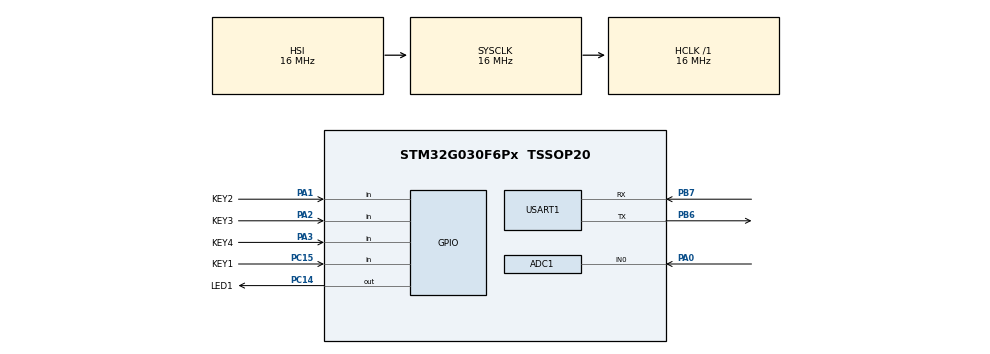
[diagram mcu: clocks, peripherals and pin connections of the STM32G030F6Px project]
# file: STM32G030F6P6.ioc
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ADC1.Channel-4\#ChannelRegularConversion=ADC_CHANNEL_0
ADC1.ContinuousConvMode=ENABLE
ADC1.DMAContinuousRequests=ENABLE
ADC1.DataAlign=ADC_DATAALIGN_RIGHT
ADC1.EOCSelection=ADC_EOC_SEQ_CONV
ADC1.NbrOfConversion=1
ADC1.NbrOfConversionFlag=1
ADC1.Overrun=ADC_OVR_DATA_PRESERVED
ADC1.Rank-4\#ChannelRegularConversion=1
ADC1.SamplingTime-4\#ChannelRegularConversion=ADC_SAMPLINGTIME_COMMON_1
ADC1.SamplingTimeCommon1=ADC_SAMPLETIME_12CYCLES_5
ADC1.SamplingTimeCommon2=ADC_SAMPLETIME_12CYCLES_5
ADC1.SelectedChannel=ADC_CHANNEL_0
ADC1.TriggerFrequencyMode=ADC_TRIGGER_FREQ_HIGH
ADC1.master=1
Dma.ADC1.0.Direction=DMA_PERIPH_TO_MEMORY
Dma.ADC1.0.EventEnable=DISABLE
Dma.ADC1.0.Instance=DMA1_Channel1
Dma.ADC1.0.MemDataAlignment=DMA_MDATAALIGN_HALFWORD
Dma.ADC1.0.MemInc=DMA_MINC_ENABLE
Dma.ADC1.0.Mode=DMA_CIRCULAR
Dma.ADC1.0.PeriphDataAlignment=DMA_PDATAALIGN_HALFWORD
Dma.ADC1.0.PeriphInc=DMA_PINC_DISABLE
Dma.ADC1.0.Polarity=HAL_DMAMUX_REQ_GEN_RISING
Dma.ADC1.0.Priority=DMA_PRIORITY_LOW
Dma.ADC1.0.RequestNumber=1
Dma.ADC1.0.SignalID=NONE
Dma.ADC1.0.SyncEnable=DISABLE
Dma.ADC1.0.SyncPolarity=HAL_DMAMUX_SYNC_NO_EVENT
Dma.ADC1.0.SyncRequestNumber=1
Dma.ADC1.0.SyncSignalID=NONE
Dma.Request0=ADC1
Mcu.Family=STM32G0
Mcu.Name=STM32G030F6Px
Mcu.Package=TSSOP20
NVIC.ADC1_IRQn=true\:0\:0\:false\:false\:true\:true\:true
NVIC.DMA1_Channel1_IRQn=true\:0\:0\:false\:false\:true\:false\:true
NVIC.USART1_IRQn=true\:0\:0\:false\:false\:true\:true\:true
PA0.GPIO_Mode=GPIO_MODE_ANALOG
PA0.GPIO_PuPd=GPIO_NOPULL
PA0.Mode=IN0
PA0.Signal=ADC1_IN0
PA1.GPIO_Label=KEY2
PA1.Signal=GPIO_Input
PA13.Mode=Serial_Wire
PA13.Signal=SYS_SWDIO
PA14-BOOT0.Mode=Serial_Wire
PA14-BOOT0.Signal=SYS_SWCLK
PA2.GPIO_Label=KEY3
PA2.Signal=GPIO_Input
PA3.GPIO_Label=KEY4
PA3.Signal=GPIO_Input
PB6.Mode=Asynchronous
PB6.Signal=USART1_TX
PB7.Mode=Asynchronous
PB7.Signal=USART1_RX
PC14-OSC32_IN\ (PC14).GPIO_Label=LED1
PC14-OSC32_IN\ (PC14).GPIO_ModeDefaultOutputPP=GPIO_MODE_OUTPUT_PP
PC14-OSC32_IN\ (PC14).PinState=GPIO_PIN_SET
PC14-OSC32_IN\ (PC14).Signal=GPIO_Output
PC15-OSC32_OUT\ (PC15).GPIO_Label=KEY1
PC15-OSC32_OUT\ (PC15).Signal=GPIO_Input
ProjectManager.HeapSize=0x200
ProjectManager.StackSize=0x400
ProjectManager.TargetToolchain=MDK-ARM V5
RCC.AHBFreq_Value=16000000
RCC.CortexFreq_Value=16000000
RCC.EXTERNAL_CLOCK_VALUE=12288000
RCC.HCLKFreq_Value=16000000
RCC.HSE_VALUE=8000000
RCC.HSI_VALUE=16000000
RCC.LSE_VALUE=32768
RCC.SYSCLKFreq_VALUE=16000000
RCC.VCOOutputFreq_Value=128000000
USART1.VirtualMode-Asynchronous=VM_ASYNC
board=custom

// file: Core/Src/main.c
/* USER CODE BEGIN Header */
/**
  ******************************************************************************
  * @file           : main.c
  * @brief          : Main program body
  ******************************************************************************
  * @attention
  *
  * <h2><center>&copy; Copyright (c) 2024 STMicroelectronics.
  * All rights reserved.</center></h2>
  *
  * This software component is licensed by ST under BSD 3-Clause license,
  * the "License"; You may not use this file except in compliance with the
  * License. You may obtain a copy of the License at:
  *                        opensource.org/licenses/BSD-3-Clause
  *
  ******************************************************************************
  */
/* USER CODE END Header */
#include "main.h"
#include "adc.h"
#include "dma.h"
#include "usart.h"
#include "gpio.h"

void SystemClock_Config(void);

int main(void)
{

  /* MCU Configuration--------------------------------------------------------*/

  /* Reset of all peripherals, Initializes the Flash interface and the Systick. */
  HAL_Init();

  /* Configure the system clock */
  SystemClock_Config();

  /* Initialize all configured peripherals */
  MX_GPIO_Init();
  MX_DMA_Init();
  MX_ADC1_Init();
  MX_USART1_UART_Init();
  /* USER CODE BEGIN 2 */

  uint16_t temp_ADC_Value;

	uint8_t tx[2];
//	temp_ADC_Value = 0x03dc;
	HAL_ADCEx_Calibration_Start(&hadc1);
	HAL_ADC_Start_DMA(&hadc1,(uint32_t*)&temp_ADC_Value, 100);
	HAL_Delay(1);

  /* USER CODE END 2 */

  /* Infinite loop */
  /* USER CODE BEGIN WHILE */
  while (1)
  {
		tx[0] =	(uint8_t)((temp_ADC_Value >> 8) & 0xFF);  //低字节
		tx[1] = (uint8_t)(temp_ADC_Value & 0xFF); //高字节
		HAL_UART_Transmit(&huart1,tx,sizeof(tx),HAL_MAX_DELAY);
		HAL_Delay(1);
    /* USER CODE END WHILE */

  }
}

void SystemClock_Config(void)
{
  RCC_OscInitTypeDef RCC_OscInitStruct = {0};
  RCC_ClkInitTypeDef RCC_ClkInitStruct = {0};
  RCC_PeriphCLKInitTypeDef PeriphClkInit = {0};

  /** Configure the main internal regulator output voltage
  */
  HAL_PWREx_ControlVoltageScaling(PWR_REGULATOR_VOLTAGE_SCALE1);
  /** Initializes the RCC Oscillators according to the specified parameters
  * in the RCC_OscInitTypeDef structure.
  */
  RCC_OscInitStruct.OscillatorType = RCC_OSCILLATORTYPE_HSI;
  RCC_OscInitStruct.HSIState = RCC_HSI_ON;
  RCC_OscInitStruct.HSIDiv = RCC_HSI_DIV1;
  RCC_OscInitStruct.HSICalibrationValue = RCC_HSICALIBRATION_DEFAULT;
  RCC_OscInitStruct.PLL.PLLState = RCC_PLL_NONE;
  if (HAL_RCC_OscConfig(&RCC_OscInitStruct) != HAL_OK)
  {
    Error_Handler();
  }
  /** Initializes the CPU, AHB and APB buses clocks
  */
  RCC_ClkInitStruct.ClockType = RCC_CLOCKTYPE_HCLK|RCC_CLOCKTYPE_SYSCLK
                              |RCC_CLOCKTYPE_PCLK1;
  RCC_ClkInitStruct.SYSCLKSource = RCC_SYSCLKSOURCE_HSI;
  RCC_ClkInitStruct.AHBCLKDivider = RCC_SYSCLK_DIV1;
  RCC_ClkInitStruct.APB1CLKDivider = RCC_HCLK_DIV1;

  if (HAL_RCC_ClockConfig(&RCC_ClkInitStruct, FLASH_LATENCY_0) != HAL_OK)
  {
    Error_Handler();
  }
  /** Initializes the peripherals clocks
  */
  PeriphClkInit.PeriphClockSelection = RCC_PERIPHCLK_USART1|RCC_PERIPHCLK_ADC;
  PeriphClkInit.Usart1ClockSelection = RCC_USART1CLKSOURCE_PCLK1;
  PeriphClkInit.AdcClockSelection = RCC_ADCCLKSOURCE_SYSCLK;
  if (HAL_RCCEx_PeriphCLKConfig(&PeriphClkInit) != HAL_OK)
  {
    Error_Handler();
  }
}

void Error_Handler(void)
{
  __disable_irq();
  while (1)
  {
  }
}

/************************ (C) COPYRIGHT STMicroelectronics *****END OF FILE****/
